# RTC register map
Vendor: Texas Instruments
Peripheral module from a debugger description file (folder ucd3138128A).
Registers are 32-bit, access not given, no defined reset value unless marked. A register's access mark holds for its fields unless they carry their own. Offsets are as the file gives them; lines under a group give offsets from that group; [hi:lo] are bit positions; {n}, {i} and the like mark numbered series; 'fields as' and 'values as' point back to an identical list; <NAME> marks a mode.

## RTC
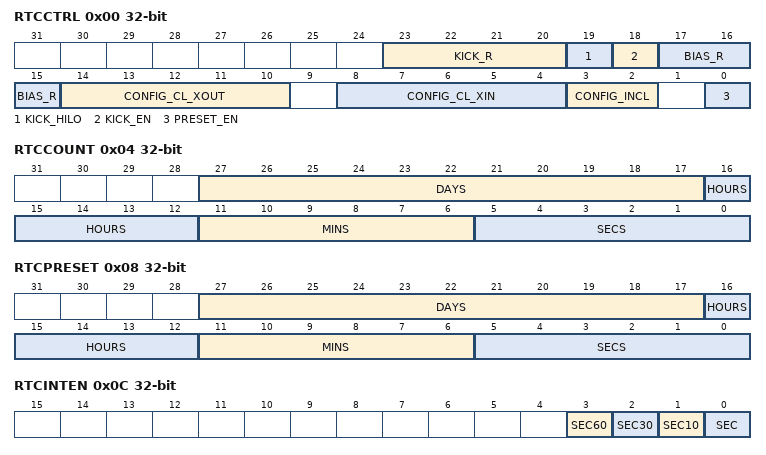
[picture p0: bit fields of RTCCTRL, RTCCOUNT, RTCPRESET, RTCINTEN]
0x00 RTCCTRL — RTC Control Register
  [23:20] KICK_R rw — Analog Kick R
  [19] KICK_HILO rw — Analog Kick Hilo
  [18] KICK_EN rw — Analog Kick En
  [17:15] BIAS_R rw — Analog Config Bias R
  [14:10] CONFIG_CL_XOUT rw — Analog Config XOUT CL
  [8:4] CONFIG_CL_XIN rw — Analog config XIN CL
  [3:2] CONFIG_INCL rw — Analog config incl
  [0] PRESET_EN rw — Preset enable
0x04 RTCCOUNT
  [27:17] DAYS rw — Count days
  [16:12] HOURS rw — Count hours
  [11:6] MINS rw — Count minutes
  [5:0] SECS rw — Count seconds
0x08 RTCPRESET — RTC Count Preset Register
  [27:17] DAYS rw — Preset days
  [16:12] HOURS rw — Preset hours
  [11:6] MINS rw — Preset minutes
  [5:0] SECS rw — Preset seconds
0x0C RTCINTEN — RTC Interrupt Enable Register
  [3] SEC60 rw — 60sec interrupt en
  [2] SEC30 rw — 30sec interrupt en
  [1] SEC10 rw — 10sec interrupt en
  [0] SEC rw — 1sec interrupt en
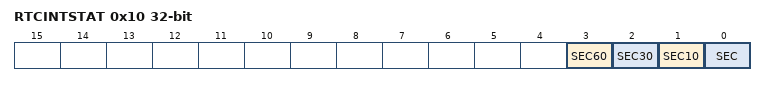
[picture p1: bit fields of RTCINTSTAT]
0x10 RTCINTSTAT — RTC Interrupt Status Register
  fields as RTCINTEN
0x14 RTCPRESCALE
  [9:0] PRESCALE rw — Prescaler value
